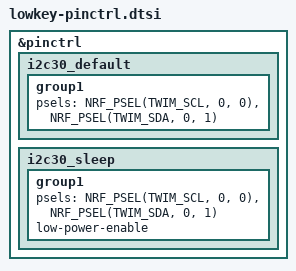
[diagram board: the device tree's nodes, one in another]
/*
 * Copyright (c) 2024 Nordic Semiconductor ASA
 * SPDX-License-Identifier: Apache-2.0
 */

&pinctrl {
	/* MAX17205 fuel gauge: SCL = P0.00, SDA = P0.01 */
	/omit-if-no-ref/ i2c30_default: i2c30_default {
		group1 {
			psels = <NRF_PSEL(TWIM_SCL, 0, 0)>,
				<NRF_PSEL(TWIM_SDA, 0, 1)>;
		};
	};

	/omit-if-no-ref/ i2c30_sleep: i2c30_sleep {
		group1 {
			psels = <NRF_PSEL(TWIM_SCL, 0, 0)>,
				<NRF_PSEL(TWIM_SDA, 0, 1)>;
			low-power-enable;
		};
	};
};
